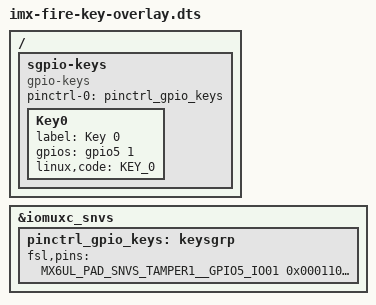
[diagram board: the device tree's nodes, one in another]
/*
 * Copyright (C) 2019 - All Rights Reserved by 
 * filename : imx-fire-key-overlay.dts
 * brief : Device Tree overlay for EBF6ull key device
 * author : embedfire
 * date : 2019-12-10
 * version : A001
 */
#include "../imx6ul-pinfunc.h"
#include "../imx6ull-pinfunc.h"
#include "../imx6ull-pinfunc-snvs.h"
#include "dt-bindings/input/linux-event-codes.h"
#include "dt-bindings/gpio/gpio.h"

/dts-v1/;
/plugin/;

/{
	
	fragment@0 {
		target-path = "/";
		__overlay__ {
			sgpio-keys {
					compatible = "gpio-keys";
					pinctrl-names = "default";
					pinctrl-0 = <&pinctrl_gpio_keys>;

					Key0{
						label = "Key 0";
						gpios = <&gpio5 1 GPIO_ACTIVE_HIGH>;
						linux,code=<KEY_0>;
				};
			};			
		};
	};
	
	fragment@1 {
		target = <&iomuxc_snvs>;
		__overlay__ {	
			pinctrl_gpio_keys: keysgrp{
				fsl,pins = <
					MX6UL_PAD_SNVS_TAMPER1__GPIO5_IO01      0x000110A1
				>;
			};	
		};
	};
};
